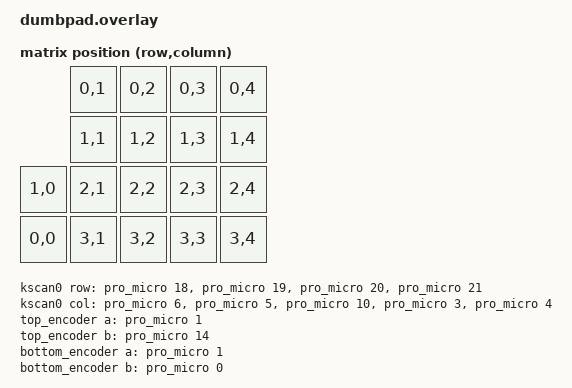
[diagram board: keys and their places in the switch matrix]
// This file was generated from a template. Edit it to match your keyboard.
// See https://zmk.dev/docs/development/hardware-integration/new-shield for more
// instructions.

#include <dt-bindings/zmk/matrix_transform.h>

#include "dumbpad-layouts.dtsi"

/ {
    chosen {
        zmk,kscan = &kscan0;
        zmk,physical-layout = &default_layout;
    };

    kscan0: kscan0 {
        // If the hardware does not use a switch matrix, change this to the
        // appropriate driver and update the properties below to match.
        // See https://zmk.dev/docs/config/kscan for supported key scan drivers.
        compatible = "zmk,kscan-gpio-matrix";
        // Set this to "col2row" or "row2col" to match the hardware. If using
        // "row2col", change the col-gpios to (GPIO_ACTIVE_HIGH | GPIO_PULL_DOWN)
        // and the row-gpios to GPIO_ACTIVE_HIGH.
        diode-direction = "col2row";
        wakeup-source;

        // Replace these comments with the GPIO pins in the matrix.
        // See https://zmk.dev/docs/development/hardware-integration/new-shield#shield-overlays
        col-gpios
            = <&pro_micro 6 (GPIO_ACTIVE_HIGH | GPIO_PULL_DOWN)>
            , <&pro_micro 5 (GPIO_ACTIVE_HIGH | GPIO_PULL_DOWN)>
            , <&pro_micro 10 (GPIO_ACTIVE_HIGH | GPIO_PULL_DOWN)>
            , <&pro_micro 3 (GPIO_ACTIVE_HIGH | GPIO_PULL_DOWN)>
            , <&pro_micro 4 (GPIO_ACTIVE_HIGH | GPIO_PULL_DOWN)>
            ;

        row-gpios
            = <&pro_micro 18 (GPIO_ACTIVE_HIGH | GPIO_PULL_DOWN)>
            , <&pro_micro 19 (GPIO_ACTIVE_HIGH | GPIO_PULL_DOWN)>
            , <&pro_micro 20 (GPIO_ACTIVE_HIGH | GPIO_PULL_DOWN)>
            , <&pro_micro 21 (GPIO_ACTIVE_HIGH | GPIO_PULL_DOWN)>
            ;
    };

    default_transform: default_transform {
        // See https://zmk.dev/docs/development/hardware-integration/new-shield#matrix-transform
        // for how to configure this
        compatible = "zmk,matrix-transform";
        columns = <5>;
        rows = <4>;

        map = <
                    RC(0,1) RC(0,2) RC(0,3) RC(0,4)
                    RC(1,1) RC(1,2) RC(1,3) RC(1,4)
            RC(1,0)	RC(2,1) RC(2,2) RC(2,3) RC(2,4)
            RC(0,0) RC(3,1) RC(3,2) RC(3,3) RC(3,4)
        >;
    };

    top_encoder: encoder_top {
        compatible = "alps,ec11";
        label = "RIGHT_ENCODER";
        a-gpios = <&pro_micro 1 (GPIO_ACTIVE_HIGH | GPIO_PULL_UP)>;
        b-gpios = <&pro_micro 14 (GPIO_ACTIVE_HIGH | GPIO_PULL_UP)>;
        resolution = <4>;
        steps = <80>;
        status = "disabled";
    };

    bottom_encoder: encoder_bottom {
        compatible = "alps,ec11";
        label = "LEFT_ENCODER";
        a-gpios = <&pro_micro 1 (GPIO_ACTIVE_HIGH | GPIO_PULL_UP)>;
        b-gpios = <&pro_micro 0  (GPIO_ACTIVE_HIGH | GPIO_PULL_UP)>;
        resolution = <4>;
        steps = <80>;
        status = "disabled";
    };

    sensors: sensors {
        compatible = "zmk,keymap-sensors";
        sensors = <&top_encoder &bottom_encoder>;
        triggers-per-rotation = <20>;
    };
};

&top_encoder {
    status = "okay";
};

&bottom_encoder {
    status = "okay";
};
